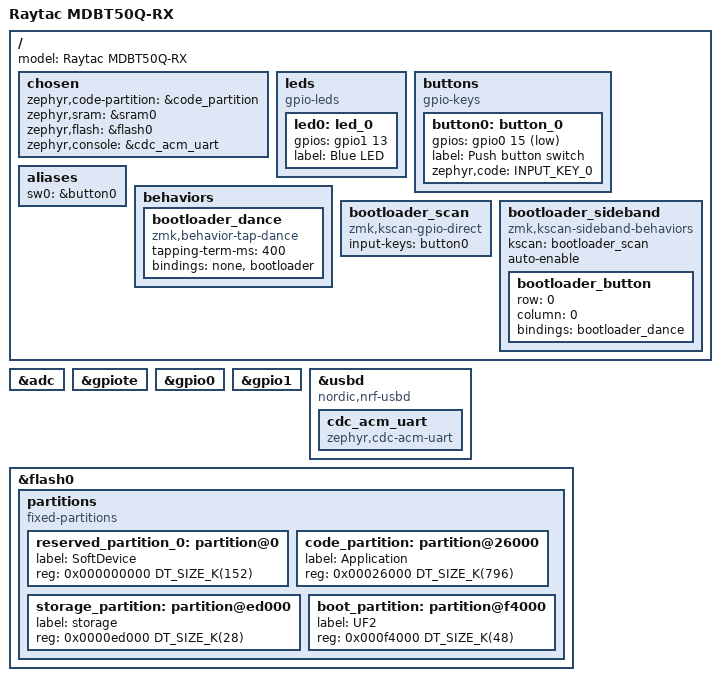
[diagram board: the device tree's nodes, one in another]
/*
 * You probably need to update the old UF2 bootloader that comes with the dongle
 * to a more recent one.
 *
 * I used these instructions:
 * https://learn.adafruit.com/introducing-the-adafruit-nrf52840-feather/update-bootloader-use-uf2
 *
 * And I used this bootloader 0.9.2:
 * https://github.com/adafruit/Adafruit_nRF52_Bootloader/releases/tag/0.9.2
 *
 * Specifically this one:
 * https://github.com/adafruit/Adafruit_nRF52_Bootloader/releases/download/0.9.2/update-raytac_mdbt50q_rx_bootloader-0.9.2_nosd.uf2
 */

/dts-v1/;
#include <nordic/nrf52840_qiaa.dtsi>
#include <zephyr/dt-bindings/input/input-event-codes.h>
#include <behaviors.dtsi>

/ {
    model = "Raytac MDBT50Q-RX";

    chosen {
        zephyr,code-partition = &code_partition;
        zephyr,sram = &sram0;
        zephyr,flash = &flash0;
        zephyr,console = &cdc_acm_uart;
    };

    leds {
        compatible = "gpio-leds";
        led0: led_0 {
            gpios = <&gpio1 13 GPIO_ACTIVE_HIGH>;
            label = "Blue LED";
        };
    };

    buttons {
        compatible = "gpio-keys";
        button0: button_0 {
            gpios = <&gpio0 15 (GPIO_PULL_UP | GPIO_ACTIVE_LOW)>;
            label = "Push button switch";
            zephyr,code = <INPUT_KEY_0>;
        };
    };

    aliases {
        sw0 = &button0;
    };

    behaviors {
        /*
         * One press does nothing; two presses within tapping-term-ms enter
         * the bootloader. See raytac_mdbt50q_cx_40.dts for why tap-dance is
         * safe to drive from a sideband runner. No &bootloader override
         * needed here — 0x57 (RST_UF2) is already correct for the RX's
         * Adafruit nRF52 bootloader.
         */
        bootloader_dance: bootloader_dance {
            compatible = "zmk,behavior-tap-dance";
            #binding-cells = <0>;
            tapping-term-ms = <400>;
            bindings = <&none>, <&bootloader>;
        };
    };

    bootloader_scan: bootloader_scan {
        compatible = "zmk,kscan-gpio-direct";
        input-keys = <&button0>;
    };

    bootloader_sideband: bootloader_sideband {
        compatible = "zmk,kscan-sideband-behaviors";
        kscan = <&bootloader_scan>;
        auto-enable;

        bootloader_button {
            row = <0>;
            column = <0>;
            bindings = <&bootloader_dance>;
        };
    };
};

&adc {
    status = "okay";
};

&gpiote {
    status = "okay";
};

&gpio0 {
    status = "okay";
};

&gpio1 {
    status = "okay";
};

zephyr_udc0: &usbd {
    compatible = "nordic,nrf-usbd";
    status = "okay";
    cdc_acm_uart: cdc_acm_uart {
        compatible = "zephyr,cdc-acm-uart";
    };
};

/* Taken from the adafruit_itsybitsy_nrf52840.dts in Zephyr.
 *
 * You can compare this to the seeeduino_xiao_ble.dts they are very similar
 */
&flash0 {
	partitions {
		compatible = "fixed-partitions";
		#address-cells = <1>;
		#size-cells = <1>;

		/* To enable flashing with UF2 bootloader, we
		 * must reserve a partition for SoftDevice.
		 * See https://learn.adafruit.com/introducing-the-adafruit-nrf52840-feather?view=all#hathach-memory-map
		 */
		reserved_partition_0: partition@0 {
			label = "SoftDevice";
			reg = <0x000000000 DT_SIZE_K(152)>;
		};
		code_partition: partition@26000 {
			label = "Application";
			reg = <0x00026000 DT_SIZE_K(796)>;
		};

		/*
		 * The flash starting at 0x000ed000 and ending at
		 * 0x000f4000 is reserved for use by the application.
		 */
		storage_partition: partition@ed000 {
			label = "storage";
			reg = <0x0000ed000 DT_SIZE_K(28)>;
		};

		boot_partition: partition@f4000 {
			label = "UF2";
			reg = <0x000f4000 DT_SIZE_K(48)>;
		};
	};
};
